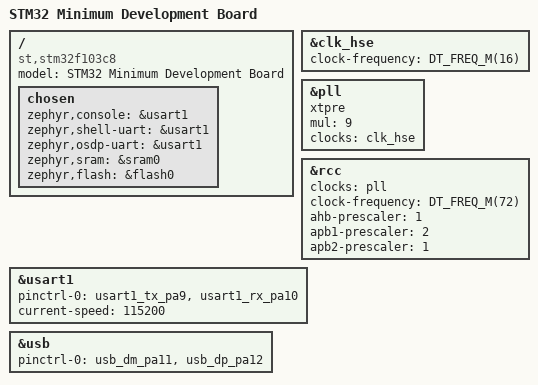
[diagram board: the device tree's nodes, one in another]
/*
 * Copyright (c) 2019, embedjournal.com
 *
 * SPDX-License-Identifier: Apache-2.0
 */

/dts-v1/;
#include <st/f1/stm32f103X8.dtsi>
#include <st/f1/stm32f103c(8-b)tx-pinctrl.dtsi>

/ {
	model = "STM32 Minimum Development Board";
	compatible = "st,stm32f103c8";

	chosen {
		zephyr,console = &usart1;
		zephyr,shell-uart = &usart1;
		zephyr,osdp-uart = &usart1;
		zephyr,sram = &sram0;
		zephyr,flash = &flash0;
	};
};

&clk_hse {
	clock-frequency = <DT_FREQ_M(16)>;
	status = "okay";
};

&pll {
	xtpre;
	mul = <9>;
	clocks = <&clk_hse>;
	status = "okay";
};

&rcc {
	clocks = <&pll>;
	clock-frequency = <DT_FREQ_M(72)>;
	ahb-prescaler = <1>;
	apb1-prescaler = <2>;
	apb2-prescaler = <1>;
	/* usbpre not set: USB clock = 72 / 1.5: 48MHz */
};

&usart1 {
	pinctrl-0 = <&usart1_tx_pa9 &usart1_rx_pa10>;
	current-speed = <115200>;
	pinctrl-names = "default";
	status = "okay";
};

zephyr_udc0: &usb {
	pinctrl-0 = <&usb_dm_pa11 &usb_dp_pa12>;
	pinctrl-names = "default";
	status = "okay";
};
